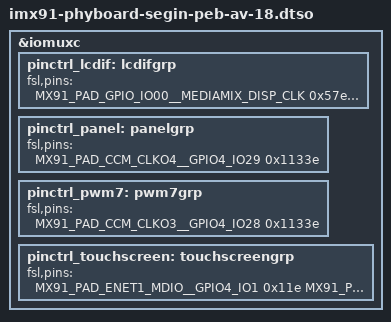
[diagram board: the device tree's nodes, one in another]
// SPDX-License-Identifier: (GPL-2.0+ OR MIT)
/*
 * Copyright (C) 2026 PHYTEC Messtechnik GmbH
 *
 * Author: Florijan Plohl <florijan.plohl@norik.com>
 */

#include "imx91-pinfunc.h"
#include "imx91-93-phyboard-segin-peb-av-18.dtsi"

&iomuxc {
	pinctrl_lcdif: lcdifgrp {
		fsl,pins = <
			MX91_PAD_GPIO_IO00__MEDIAMIX_DISP_CLK		0x57e
			MX91_PAD_GPIO_IO01__MEDIAMIX_DISP_DE		0x51e
			MX91_PAD_GPIO_IO02__MEDIAMIX_DISP_VSYNC		0x51e
			MX91_PAD_GPIO_IO03__MEDIAMIX_DISP_HSYNC		0x51e
			MX91_PAD_GPIO_IO04__MEDIAMIX_DISP_DATA0 	0x51e
			MX91_PAD_GPIO_IO05__MEDIAMIX_DISP_DATA1		0x51e
			MX91_PAD_GPIO_IO06__MEDIAMIX_DISP_DATA2		0x51e
			MX91_PAD_GPIO_IO07__MEDIAMIX_DISP_DATA3		0x51e
			MX91_PAD_GPIO_IO08__MEDIAMIX_DISP_DATA4		0x51e
			MX91_PAD_GPIO_IO09__MEDIAMIX_DISP_DATA5		0x51e
			MX91_PAD_GPIO_IO10__MEDIAMIX_DISP_DATA6		0x51e
			MX91_PAD_GPIO_IO11__MEDIAMIX_DISP_DATA7		0x51e
			MX91_PAD_GPIO_IO12__MEDIAMIX_DISP_DATA8		0x51e
			MX91_PAD_GPIO_IO13__MEDIAMIX_DISP_DATA9		0x51e
			MX91_PAD_GPIO_IO14__MEDIAMIX_DISP_DATA10	0x51e
			MX91_PAD_GPIO_IO15__MEDIAMIX_DISP_DATA11	0x51e
			MX91_PAD_GPIO_IO16__MEDIAMIX_DISP_DATA12	0x51e
			MX91_PAD_GPIO_IO17__MEDIAMIX_DISP_DATA13	0x51e
			MX91_PAD_GPIO_IO18__MEDIAMIX_DISP_DATA14	0x51e
			MX91_PAD_GPIO_IO19__MEDIAMIX_DISP_DATA15	0x51e
			MX91_PAD_GPIO_IO20__MEDIAMIX_DISP_DATA16	0x51e
			MX91_PAD_GPIO_IO21__MEDIAMIX_DISP_DATA17	0x51e
		>;
	};

	pinctrl_panel: panelgrp {
		fsl,pins = <
			MX91_PAD_CCM_CLKO4__GPIO4_IO29			0x1133e
		>;
	};

	pinctrl_pwm7: pwm7grp {
		fsl,pins = <
			MX91_PAD_CCM_CLKO3__GPIO4_IO28			0x1133e
		>;
	};

	pinctrl_touchscreen: touchscreengrp {
		fsl,pins = <
			MX91_PAD_ENET1_MDIO__GPIO4_IO1			0x11e
			MX91_PAD_ENET1_RD2__GPIO4_IO12			0x1133e
		>;
	};
};
